# PIC32MK0512GPL100 register map
Vendor: Microchip
Registers are 32-bit, read-write, no defined reset value unless marked. A register's access mark holds for its fields unless they carry their own. Addresses are absolute, and some are shared; only a register's first bit layout is shown; [hi:lo] are bit positions.

## SPI6
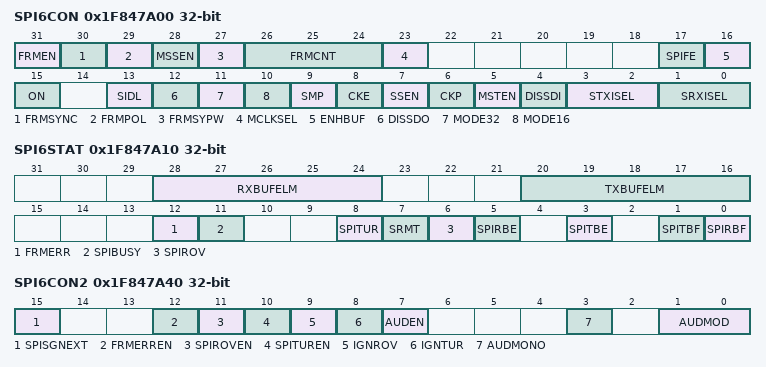
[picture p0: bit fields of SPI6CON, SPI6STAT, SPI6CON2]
0x1F847A00 SPI6CON — (power-on value 00000000x-----0000000000000x0000)
  [31] FRMEN, [30] FRMSYNC, [29] FRMPOL, [28] MSSEN, [27] FRMSYPW, [26:24] FRMCNT, [23] MCLKSEL, [17] SPIFE, [16] ENHBUF, [15] ON, [13] SIDL, [12] DISSDO, [11] MODE32, [10] MODE16, [9] SMP, [8] CKE, [7] SSEN, [6] CKP, [5] MSTEN, [4] DISSDI, [3:2] STXISEL, [1:0] SRXISEL
0x1F847A10 SPI6STAT — (power-on value ---00000---00000---x0--0000-0-00)
  [28:24] RXBUFELM ro, [20:16] TXBUFELM ro, [12] FRMERR, [11] SPIBUSY ro, [8] SPITUR ro, [7] SRMT ro, [6] SPIROV ro, [5] SPIRBE ro, [3] SPITBE ro, [1] SPITBF ro, [0] SPIRBF ro
0x1F847A20 SPI6BUF — (power-on value xxxxxxxxxxxxxxxxxxxxxxxxxxxxxxxx)
0x1F847A30 SPI6BRG — (power-on value -------------------xxxxxxxxxxxxx)
  [12:0] SPI6BRG
0x1F847A40 SPI6CON2 — (power-on value ----------------x--xxxxxx---x-xx)
  [15] SPISGNEXT, [12] FRMERREN, [11] SPIROVEN, [10] SPITUREN, [9] IGNROV, [8] IGNTUR, [7] AUDEN, [3] AUDMONO, [1:0] AUDMOD

## UART3
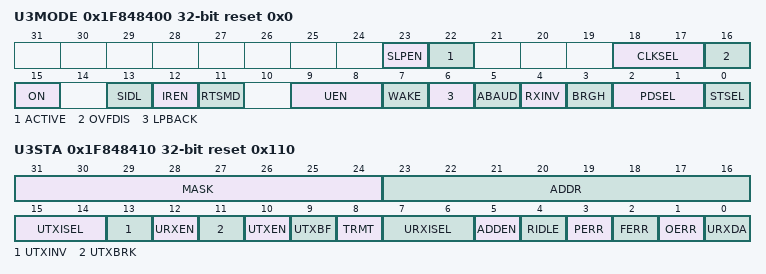
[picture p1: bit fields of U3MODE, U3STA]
0x1F848400 U3MODE reset 0x0
  [23] SLPEN, [22] ACTIVE, [18:17] CLKSEL, [16] OVFDIS, [15] ON, [13] SIDL, [12] IREN, [11] RTSMD, [9:8] UEN, [7] WAKE, [6] LPBACK, [5] ABAUD, [4] RXINV, [3] BRGH, [2:1] PDSEL, [0] STSEL
0x1F848410 U3STA reset 0x110
  [31:24] MASK
  [23:16] ADDR
  [15:14] UTXISEL
  [13] UTXINV
  [12] URXEN
  [11] UTXBRK
  [10] UTXEN
  [9] UTXBF ro
  [8] TRMT ro
  [7:6] URXISEL
  [5] ADDEN
  [4] RIDLE ro
  [3] PERR ro
  [2] FERR ro
  [1] OERR — (can only be cleared)
  [0] URXDA ro
0x1F848420 U3TXREG reset 0x0
  [8:0] U3TXREG
0x1F848430 U3RXREG ro reset 0x0
  [8:0] U3RXREG
0x1F848440 U3BRG reset 0x0
  [19:0] BRG

## UART4
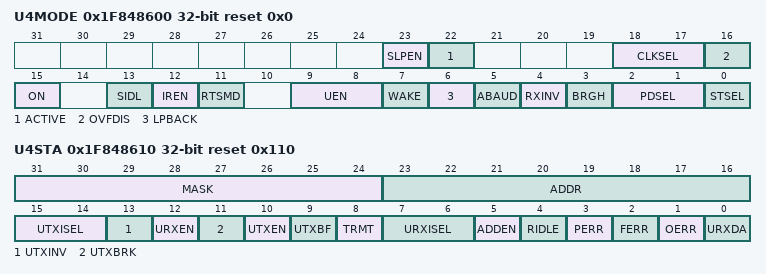
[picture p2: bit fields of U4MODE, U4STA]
0x1F848600 U4MODE reset 0x0
  [23] SLPEN, [22] ACTIVE, [18:17] CLKSEL, [16] OVFDIS, [15] ON, [13] SIDL, [12] IREN, [11] RTSMD, [9:8] UEN, [7] WAKE, [6] LPBACK, [5] ABAUD, [4] RXINV, [3] BRGH, [2:1] PDSEL, [0] STSEL
0x1F848610 U4STA reset 0x110
  [31:24] MASK
  [23:16] ADDR
  [15:14] UTXISEL
  [13] UTXINV
  [12] URXEN
  [11] UTXBRK
  [10] UTXEN
  [9] UTXBF ro
  [8] TRMT ro
  [7:6] URXISEL
  [5] ADDEN
  [4] RIDLE ro
  [3] PERR ro
  [2] FERR ro
  [1] OERR — (can only be cleared)
  [0] URXDA ro
0x1F848620 U4TXREG reset 0x0
  [8:0] U4TXREG
0x1F848630 U4RXREG ro reset 0x0
  [8:0] U4RXREG
0x1F848640 U4BRG reset 0x0
  [19:0] BRG

## UART5
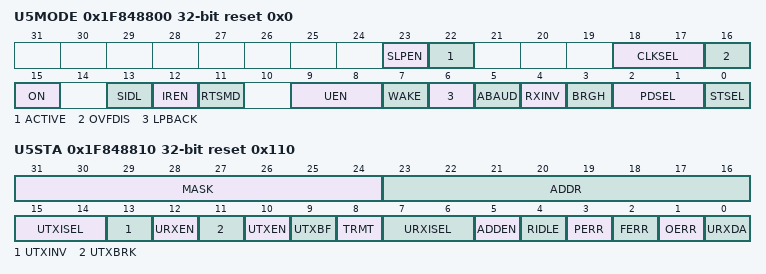
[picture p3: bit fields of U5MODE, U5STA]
0x1F848800 U5MODE reset 0x0
  [23] SLPEN, [22] ACTIVE, [18:17] CLKSEL, [16] OVFDIS, [15] ON, [13] SIDL, [12] IREN, [11] RTSMD, [9:8] UEN, [7] WAKE, [6] LPBACK, [5] ABAUD, [4] RXINV, [3] BRGH, [2:1] PDSEL, [0] STSEL
0x1F848810 U5STA reset 0x110
  [31:24] MASK
  [23:16] ADDR
  [15:14] UTXISEL
  [13] UTXINV
  [12] URXEN
  [11] UTXBRK
  [10] UTXEN
  [9] UTXBF ro
  [8] TRMT ro
  [7:6] URXISEL
  [5] ADDEN
  [4] RIDLE ro
  [3] PERR ro
  [2] FERR ro
  [1] OERR — (can only be cleared)
  [0] URXDA ro
0x1F848820 U5TXREG reset 0x0
  [8:0] U5TXREG
0x1F848830 U5RXREG ro reset 0x0
  [8:0] U5RXREG
0x1F848840 U5BRG reset 0x0
  [19:0] BRG

## UART6
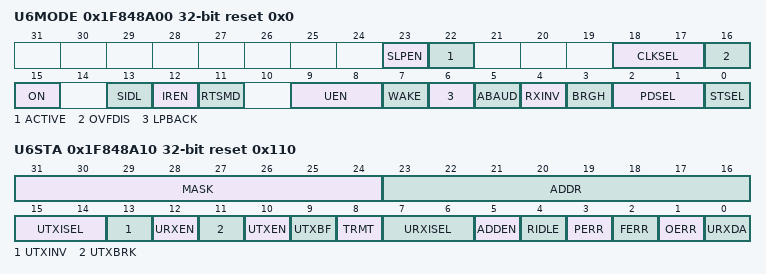
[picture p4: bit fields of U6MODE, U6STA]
0x1F848A00 U6MODE reset 0x0
  [23] SLPEN, [22] ACTIVE, [18:17] CLKSEL, [16] OVFDIS, [15] ON, [13] SIDL, [12] IREN, [11] RTSMD, [9:8] UEN, [7] WAKE, [6] LPBACK, [5] ABAUD, [4] RXINV, [3] BRGH, [2:1] PDSEL, [0] STSEL
0x1F848A10 U6STA reset 0x110
  [31:24] MASK
  [23:16] ADDR
  [15:14] UTXISEL
  [13] UTXINV
  [12] URXEN
  [11] UTXBRK
  [10] UTXEN
  [9] UTXBF ro
  [8] TRMT ro
  [7:6] URXISEL
  [5] ADDEN
  [4] RIDLE ro
  [3] PERR ro
  [2] FERR ro
  [1] OERR — (can only be cleared)
  [0] URXDA ro
0x1F848A20 U6TXREG reset 0x0
  [8:0] U6TXREG
0x1F848A30 U6RXREG ro reset 0x0
  [8:0] U6RXREG
0x1F848A40 U6BRG reset 0x0
  [19:0] BRG

## CDAC2
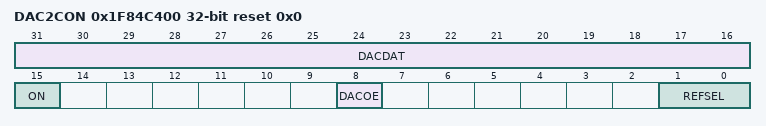
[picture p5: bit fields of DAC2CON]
0x1F84C400 DAC2CON reset 0x0 — CDAC Control Register
  [31:16] DACDAT — Data Input Register Bits for the CDAC
  [15] ON — CDAC Enable
    0=The CDAC is Disabled; 1=The CDAC is Enabled
  [8] DACOE — CDAC Output Enable
    0=Output is Disabled; drive to pin is floating; 1=Output is Enabled; CDAC voltage is connected to the pin
  [1:0] REFSEL — Reference Source Select
    0=No Reference Selected (no current consumed); 1=Positive Reference Voltage = External Vref+ Pin; 2=Positive Reference Voltage = 2 * Internal Bandgap Reference Voltage; 3=Positive Reference Voltage = AVdd
